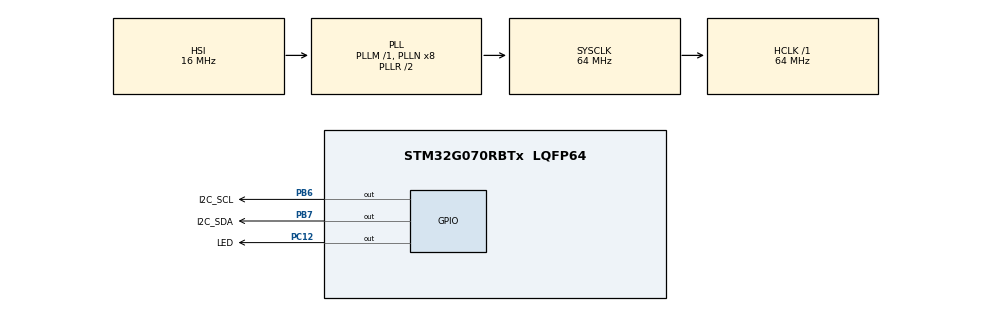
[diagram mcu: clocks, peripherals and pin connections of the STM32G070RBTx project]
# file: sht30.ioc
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Mcu.Family=STM32G0
Mcu.Name=STM32G070RBTx
Mcu.Package=LQFP64
PA13.Mode=Serial_Wire
PA13.Signal=SYS_SWDIO
PA14-BOOT0.Mode=Serial_Wire
PA14-BOOT0.Signal=SYS_SWCLK
PB6.GPIO_Label=I2C_SCL
PB6.Signal=GPIO_Output
PB7.GPIO_Label=I2C_SDA
PB7.Signal=GPIO_Output
PC12.GPIO_Label=LED
PC12.Signal=GPIO_Output
ProjectManager.HeapSize=0x200
ProjectManager.StackSize=0x400
ProjectManager.TargetToolchain=CMake
RCC.ADCFreq_Value=64000000
RCC.AHBFreq_Value=64000000
RCC.CortexFreq_Value=64000000
RCC.EXTERNAL_CLOCK_VALUE=48000
RCC.HCLKFreq_Value=64000000
RCC.HSE_VALUE=8000000
RCC.HSI_VALUE=16000000
RCC.LSE_VALUE=32768
RCC.SYSCLKFreq_VALUE=64000000
RCC.SYSCLKSource=RCC_SYSCLKSOURCE_PLLCLK
RCC.VCOOutputFreq_Value=128000000
board=custom

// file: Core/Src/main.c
/* USER CODE BEGIN Header */
/**
 ******************************************************************************
 * @file           : main.c
 * @brief          : Main program body
 ******************************************************************************
 * @attention
 *
 * Copyright (c) 2025 STMicroelectronics.
 * All rights reserved.
 *
 * This software is licensed under terms that can be found in the LICENSE file
 * in the root directory of this software component.
 * If no LICENSE file comes with this software, it is provided AS-IS.
 *
 ******************************************************************************
 */
/* USER CODE END Header */
#include "main.h"
#include "gpio.h"
#include "stm32g0xx_hal.h"
#include "stm32g0xx_hal_gpio.h"

/* USER CODE BEGIN Includes */
#include "log.h"
#include "soft_i2c.h"
#include "mnumber.h"
/* USER CODE END Includes */

void SystemClock_Config(void);

/* USER CODE BEGIN 0 */
void i2c_scnner_cb_func(uint8_t address, bool result)
{
    if (result)
    {
        log_debug("Found device at address[7bit]: 0x%02X", address);
    }

    // wait
    HAL_Delay(20);
}

void sht30_sample(float *temp, float *humi)
{
    uint8_t rd_buff[6] = {0};
    uint8_t cmd[2] = {0x20, 0x32};

    uint8_t dev_addr = 0x44;

    // send read cmd
    soft_i2c_transfer(dev_addr, cmd, 2, 0, 0);

    // some sensor need more waite time
    HAL_Delay(20);

    // receive data
    soft_i2c_transfer(dev_addr, 0, 0, rd_buff, 6);

    uint16_t temp_int = (uint16_t)((rd_buff[0] << 8) | (rd_buff[1]));
    uint16_t humi_int = (uint16_t)((rd_buff[3] << 8) | (rd_buff[4]));

    *temp = -45 + (float)(175 * temp_int / 65535.0000);
    *humi = 100 * (float)(humi_int / 65535.0000);
}

/* USER CODE END 0 */

int main(void)
{

    /* MCU Configuration--------------------------------------------------------*/

    /* Reset of all peripherals, Initializes the Flash interface and the Systick.
     */
    HAL_Init();

    /* Configure the system clock */
    SystemClock_Config();

    /* Initialize all configured peripherals */
    MX_GPIO_Init();
    /* USER CODE BEGIN 2 */
    log_init(LOG_TRACE, false);
    log_info("app started.");

    soft_i2c_init();
    log_info("scan i2c bus...");
    scan_i2c_bus(0x0, 0x4f, i2c_scnner_cb_func);
    log_info("scan i2c bus done.");

    /* USER CODE END 2 */

    /* Infinite loop */
    while (1)
    {

        /* USER CODE BEGIN 3 */
        HAL_GPIO_WritePin(LED_GPIO_Port, LED_Pin, GPIO_PIN_RESET);
        HAL_Delay(300);

        HAL_GPIO_WritePin(LED_GPIO_Port, LED_Pin, GPIO_PIN_SET);
        HAL_Delay(300);

        float t, h;
        sht30_sample(&t, &h);

        char buff_t[32];
        char buff_h[32];
        float_to_string(buff_t, t);
        float_to_string(buff_h, h);

        log_debug("t: %s, h: %s", buff_t, buff_h);
    }
    /* USER CODE END 3 */
}

void SystemClock_Config(void)
{
    RCC_OscInitTypeDef RCC_OscInitStruct = {0};
    RCC_ClkInitTypeDef RCC_ClkInitStruct = {0};

    /** Configure the main internal regulator output voltage
     */
    HAL_PWREx_ControlVoltageScaling(PWR_REGULATOR_VOLTAGE_SCALE1);

    /** Initializes the RCC Oscillators according to the specified parameters
     * in the RCC_OscInitTypeDef structure.
     */
    RCC_OscInitStruct.OscillatorType = RCC_OSCILLATORTYPE_HSI;
    RCC_OscInitStruct.HSIState = RCC_HSI_ON;
    RCC_OscInitStruct.HSIDiv = RCC_HSI_DIV1;
    RCC_OscInitStruct.HSICalibrationValue = RCC_HSICALIBRATION_DEFAULT;
    RCC_OscInitStruct.PLL.PLLState = RCC_PLL_ON;
    RCC_OscInitStruct.PLL.PLLSource = RCC_PLLSOURCE_HSI;
    RCC_OscInitStruct.PLL.PLLM = RCC_PLLM_DIV1;
    RCC_OscInitStruct.PLL.PLLN = 8;
    RCC_OscInitStruct.PLL.PLLP = RCC_PLLP_DIV2;
    RCC_OscInitStruct.PLL.PLLR = RCC_PLLR_DIV2;
    if (HAL_RCC_OscConfig(&RCC_OscInitStruct) != HAL_OK)
    {
        Error_Handler();
    }

    /** Initializes the CPU, AHB and APB buses clocks
     */
    RCC_ClkInitStruct.ClockType =
        RCC_CLOCKTYPE_HCLK | RCC_CLOCKTYPE_SYSCLK | RCC_CLOCKTYPE_PCLK1;
    RCC_ClkInitStruct.SYSCLKSource = RCC_SYSCLKSOURCE_PLLCLK;
    RCC_ClkInitStruct.AHBCLKDivider = RCC_SYSCLK_DIV1;
    RCC_ClkInitStruct.APB1CLKDivider = RCC_HCLK_DIV1;

    if (HAL_RCC_ClockConfig(&RCC_ClkInitStruct, FLASH_LATENCY_2) != HAL_OK)
    {
        Error_Handler();
    }
}

void Error_Handler(void)
{
    __disable_irq();
    while (1)
    {
    }
}

#ifdef USE_FULL_ASSERT
/**
 * @brief  Reports the name of the source file and the source line number
 *         where the assert_param error has occurred.
 * @param  file: pointer to the source file name
 * @param  line: assert_param error line source number
 * @retval None
 */
void assert_failed(uint8_t *file, uint32_t line)
{
    /* USER CODE BEGIN 6 */
    /* User can add his own implementation to report the file name and line
       number, ex: printf("Wrong parameters value: file %s on line %d\r\n", file,
       line) */
    /* USER CODE END 6 */
}
#endif /* USE_FULL_ASSERT */
